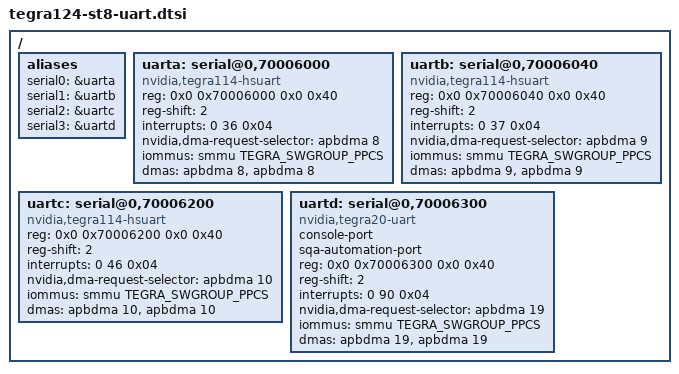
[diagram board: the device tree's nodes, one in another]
#include <dt-bindings/gpio/tegra-gpio.h>

/ {
    aliases {
        serial0 = &uarta;
        serial1 = &uartb;
        serial2 = &uartc;
        serial3 = &uartd;
    };
    
    /*
     * There are two serial driver i.e. 8250 based simple serial
     * driver and APB DMA based serial driver for higher baudrate
     * and performace. To enable the 8250 based driver, the compatible
     * is "nvidia,tegra114-uart", "nvidia,tegra20-uart" and to enable
     * the APB DMA based serial driver, the comptible is
     * "nvidia,tegra114-hsuart", "nvidia,tegra30-hsuart".
     */
    uarta: serial@0,70006000 {
        compatible = "nvidia,tegra114-hsuart", "nvidia,tegra124-uart";
        status = "okay";
        reg = <0x0 0x70006000 0x0 0x40>;
        reg-shift = <2>;
        interrupts = <0 36 0x04>;
        nvidia,dma-request-selector = <&apbdma 8>;
        iommus = <&smmu TEGRA_SWGROUP_PPCS>;
        dmas = <&apbdma 8>, <&apbdma 8>;
        dma-names = "rx", "tx";
    };
    
    uartb: serial@0,70006040 {
        compatible = "nvidia,tegra114-hsuart", "nvidia,tegra124-uart";
        status = "okay";
        reg = <0x0 0x70006040 0x0 0x40>;
        reg-shift = <2>;
        interrupts = <0 37 0x04>;
        nvidia,dma-request-selector = <&apbdma 9>;
        iommus = <&smmu TEGRA_SWGROUP_PPCS>;
        dmas = <&apbdma 9>, <&apbdma 9>;
        dma-names = "rx", "tx";
    };
    
    uartc: serial@0,70006200 {
        compatible = "nvidia,tegra114-hsuart", "nvidia,tegra124-uart";
        status = "okay";
        reg = <0x0 0x70006200 0x0 0x40>;
        reg-shift = <2>;
        interrupts = <0 46 0x04>;
        nvidia,dma-request-selector = <&apbdma 10>;
        iommus = <&smmu TEGRA_SWGROUP_PPCS>;
        dmas = <&apbdma 10>, <&apbdma 10>;
        dma-names = "rx", "tx";
    };
    
    uartd: serial@0,70006300 {
        compatible = "nvidia,tegra20-uart", "nvidia,tegra124-uart", "nvidia,tegra114-hsuart";
        console-port;
        sqa-automation-port;
        status = "okay";
        reg = <0x0 0x70006300 0x0 0x40>;
        reg-shift = <2>;
        interrupts = <0 90 0x04>;
        nvidia,dma-request-selector = <&apbdma 19>;
        iommus = <&smmu TEGRA_SWGROUP_PPCS>;
        dmas = <&apbdma 19>, <&apbdma 19>;
        dma-names = "rx", "tx";
    };
};
